AUTOSAR XML (schema 4-2-2)
package /Components
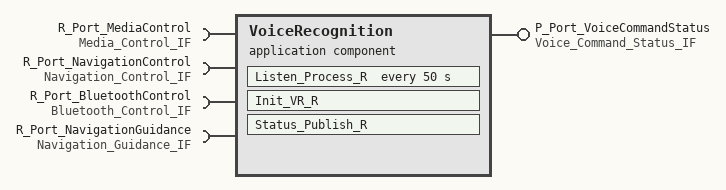
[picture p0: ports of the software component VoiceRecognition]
  application sw component type VoiceRecognition
    provide port P_Port_VoiceCommandStatus: provided-interface=Voice_Command_Status_IF
    4 x require port:
      R_Port_MediaControl: required-interface=Media_Control_IF
      R_Port_NavigationControl: required-interface=Navigation_Control_IF
      R_Port_BluetoothControl: required-interface=Bluetooth_Control_IF
      R_Port_NavigationGuidance: required-interface=Navigation_Guidance_IF
    behavior VoiceRecognition_Internal
      init event VR_Init: start-on-event=Init_VR_R
      timing event VR_Periodic: start-on-event=Listen_Process_R, period=50
      runnable Init_VR_R: symbol=Init_VR
        parameter access ParamAccess_DefaultConfidence: accessed-parameter=P_Port_VoiceCommandStatus.confidence
        parameter access ParamAccess_DefaultCommandResult: accessed-parameter=P_Port_VoiceCommandStatus.command_result
      runnable Listen_Process_R: minimum-start-interval=50, symbol=Listen_Process
        15 x sync call:
          SC_Media_Play: operation=R_Port_MediaControl.Play, timeout=50
          SC_Media_Pause: operation=R_Port_MediaControl.Pause, timeout=50
          SC_Media_Stop: operation=R_Port_MediaControl.Stop, timeout=50
          SC_Media_NextTrack: operation=R_Port_MediaControl.NextTrack, timeout=50
          SC_Media_PreviousTrack: operation=R_Port_MediaControl.PreviousTrack, timeout=50
          SC_Media_SetSource: operation=R_Port_MediaControl.SetSource, timeout=50
          SC_Nav_StartRoute: operation=R_Port_NavigationControl.StartRoute, timeout=200
          SC_Nav_CancelRoute: operation=R_Port_NavigationControl.CancelRoute, timeout=200
          SC_Nav_SetDestination: operation=R_Port_NavigationControl.SetDestination, timeout=200
          SC_BT_Pair: operation=R_Port_BluetoothControl.Pair, timeout=200
          SC_BT_ConnectAudio: operation=R_Port_BluetoothControl.ConnectAudio, timeout=200
          SC_BT_ConnectPhone: operation=R_Port_BluetoothControl.ConnectPhone, timeout=200
          SC_BT_DialNumber: operation=R_Port_BluetoothControl.DialNumber, timeout=200
          SC_BT_AnswerCall: operation=R_Port_BluetoothControl.AnswerCall, timeout=200
          SC_BT_Hangup: operation=R_Port_BluetoothControl.Hangup, timeout=200
      runnable Status_Publish_R: symbol=Status_Publish
        data-send-points:
          access Send_CommandResult: accessed-variable=P_Port_VoiceCommandStatus.command_result
          access Send_Confidence: accessed-variable=P_Port_VoiceCommandStatus.confidence
